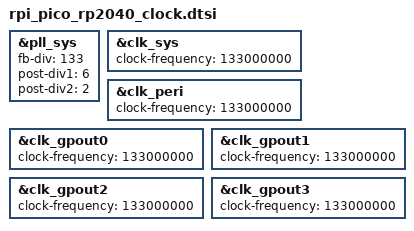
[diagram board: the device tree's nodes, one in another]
/*
 * The RP2040 at 133 MHz, the highest clock it is rated for at the core
 * voltage it starts with (1.10 V); Zephyr runs it at 125 MHz. 200 MHz, rated
 * since 2025, needs 1.15 V, which Zephyr does not set. The system PLL:
 * 12 MHz x 133 = 1596 MHz, divided by 6 and by 2. Every clock taken from it
 * says so, for the drivers that read their rate (UART, PIO SPI to the WiFi
 * chip) and for the kernel's cycle count. The flash is read at half the
 * system clock (66.5 MHz): MCUboot's second-stage boot sets that.
 */
&pll_sys {
	fb-div = <133>;
	post-div1 = <6>;
	post-div2 = <2>;
};

&clk_sys {
	clock-frequency = <133000000>;
};

&clk_peri {
	clock-frequency = <133000000>;
};

&clk_gpout0 {
	clock-frequency = <133000000>;
};

&clk_gpout1 {
	clock-frequency = <133000000>;
};

&clk_gpout2 {
	clock-frequency = <133000000>;
};

&clk_gpout3 {
	clock-frequency = <133000000>;
};
